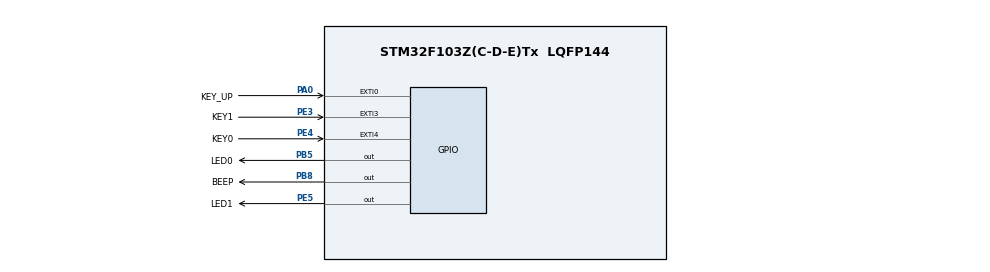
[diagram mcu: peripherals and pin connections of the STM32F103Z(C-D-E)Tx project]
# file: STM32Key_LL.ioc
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Mcu.Family=STM32F1
Mcu.Name=STM32F103Z(C-D-E)Tx
Mcu.Package=LQFP144
NVIC.EXTI0_IRQn=true\:0\:0\:false\:false\:true\:true\:true\:true
NVIC.EXTI3_IRQn=true\:0\:0\:false\:false\:true\:true\:true\:true
NVIC.EXTI4_IRQn=true\:0\:0\:false\:false\:true\:true\:true\:true
NVIC.PriorityGroup=NVIC_PRIORITYGROUP_4
OSC_IN.Mode=HSE-External-Oscillator
OSC_IN.Signal=RCC_OSC_IN
OSC_OUT.Mode=HSE-External-Oscillator
OSC_OUT.Signal=RCC_OSC_OUT
PA0-WKUP.GPIO_Label=KEY_UP
PA0-WKUP.GPIO_ModeDefaultEXTI=GPIO_MODE_IT_FALLING
PA0-WKUP.GPIO_PuPd=GPIO_PULLDOWN
PA0-WKUP.Signal=GPXTI0
PA13.Mode=Serial_Wire
PA13.Signal=SYS_JTMS-SWDIO
PA14.Mode=Serial_Wire
PA14.Signal=SYS_JTCK-SWCLK
PB5.GPIO_Label=LED0
PB5.PinState=GPIO_PIN_SET
PB5.Signal=GPIO_Output
PB8.GPIO_Label=BEEP
PB8.PinState=GPIO_PIN_SET
PB8.Signal=GPIO_Output
PC14-OSC32_IN.Mode=LSE-External-Oscillator
PC14-OSC32_IN.Signal=RCC_OSC32_IN
PC15-OSC32_OUT.Mode=LSE-External-Oscillator
PC15-OSC32_OUT.Signal=RCC_OSC32_OUT
PE3.GPIO_Label=KEY1
PE3.GPIO_ModeDefaultEXTI=GPIO_MODE_IT_FALLING
PE3.GPIO_PuPd=GPIO_PULLUP
PE3.Signal=GPXTI3
PE4.GPIO_Label=KEY0
PE4.GPIO_ModeDefaultEXTI=GPIO_MODE_IT_FALLING
PE4.GPIO_PuPd=GPIO_PULLUP
PE4.Signal=GPXTI4
PE5.GPIO_Label=LED1
PE5.PinState=GPIO_PIN_SET
PE5.Signal=GPIO_Output
ProjectManager.HeapSize=0x200
ProjectManager.StackSize=0x400
ProjectManager.TargetToolchain=MDK-ARM V5
RCC.AHBFreq_Value=72000000
RCC.APB1CLKDivider=RCC_HCLK_DIV2
RCC.APB1Freq_Value=36000000
RCC.APB1TimFreq_Value=72000000
RCC.APB2Freq_Value=72000000
RCC.APB2TimFreq_Value=72000000
RCC.HCLKFreq_Value=72000000
RCC.PLLMUL=RCC_PLL_MUL9
RCC.PLLSourceVirtual=RCC_PLLSOURCE_HSE
RCC.SYSCLKFreq_VALUE=72000000
RCC.SYSCLKSource=RCC_SYSCLKSOURCE_PLLCLK
RCC.USBFreq_Value=72000000
board=custom

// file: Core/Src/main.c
/* USER CODE BEGIN Header */
/**
  ******************************************************************************
  * @file           : main.c
  * @brief          : Main program body
  ******************************************************************************
  * @attention
  *
  * Copyright (c) 2025 STMicroelectronics.
  * All rights reserved.
  *
  * This software is licensed under terms that can be found in the LICENSE file
  * in the root directory of this software component.
  * If no LICENSE file comes with this software, it is provided AS-IS.
  *
  ******************************************************************************
  */
/* USER CODE END Header */
#include "main.h"
#include "gpio.h"

void SystemClock_Config(void);

int main(void)
{

  /* MCU Configuration--------------------------------------------------------*/

  /* Reset of all peripherals, Initializes the Flash interface and the Systick. */
  LL_APB2_GRP1_EnableClock(LL_APB2_GRP1_PERIPH_AFIO);
  LL_APB1_GRP1_EnableClock(LL_APB1_GRP1_PERIPH_PWR);

  /* System interrupt init*/
  NVIC_SetPriorityGrouping(NVIC_PRIORITYGROUP_4);

  /* SysTick_IRQn interrupt configuration */
  NVIC_SetPriority(SysTick_IRQn, NVIC_EncodePriority(NVIC_GetPriorityGrouping(),15, 0));

  /** NOJTAG: JTAG-DP Disabled and SW-DP Enabled
  */
  LL_GPIO_AF_Remap_SWJ_NOJTAG();

  /* Configure the system clock */
  SystemClock_Config();

  /* Initialize all configured peripherals */
  MX_GPIO_Init();
  /* USER CODE BEGIN 2 */
  LED0_OFF;
  LED1_OFF;
  BEEP_OFF;

  /* USER CODE END 2 */

  /* Infinite loop */
  while (1)
  {

  }
}

void SystemClock_Config(void)
{
  LL_FLASH_SetLatency(LL_FLASH_LATENCY_2);
  while(LL_FLASH_GetLatency()!= LL_FLASH_LATENCY_2)
  {
  }
  LL_RCC_HSE_Enable();

   /* Wait till HSE is ready */
  while(LL_RCC_HSE_IsReady() != 1)
  {

  }
  LL_RCC_PLL_ConfigDomain_SYS(LL_RCC_PLLSOURCE_HSE_DIV_1, LL_RCC_PLL_MUL_9);
  LL_RCC_PLL_Enable();

   /* Wait till PLL is ready */
  while(LL_RCC_PLL_IsReady() != 1)
  {

  }
  LL_RCC_SetAHBPrescaler(LL_RCC_SYSCLK_DIV_1);
  LL_RCC_SetAPB1Prescaler(LL_RCC_APB1_DIV_2);
  LL_RCC_SetAPB2Prescaler(LL_RCC_APB2_DIV_1);
  LL_RCC_SetSysClkSource(LL_RCC_SYS_CLKSOURCE_PLL);

   /* Wait till System clock is ready */
  while(LL_RCC_GetSysClkSource() != LL_RCC_SYS_CLKSOURCE_STATUS_PLL)
  {

  }
  LL_Init1msTick(72000000);
  LL_SetSystemCoreClock(72000000);
}

void Error_Handler(void)
{
  __disable_irq();
  while (1)
  {
  }
}
